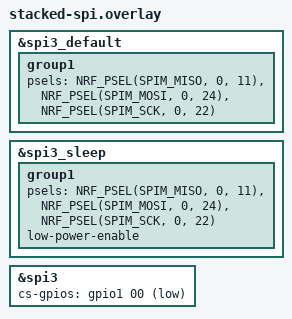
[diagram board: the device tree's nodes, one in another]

// Disable i2c

/* &i2c0_default {
    group1 {
        psels = <NRF_PSEL(TWIM_SDA, 1, 13)>, <NRF_PSEL(TWIM_SCL, 1, 15)>;
    };
};

&i2c0_sleep {
    group1 {
        psels = <NRF_PSEL(TWIM_SDA, 1, 13)>, <NRF_PSEL(TWIM_SCL, 1, 15)>;
    };
}; */

/delete-node/ &imu;
/delete-node/ &mag;




&spi3_default {
    group1 {
        psels = <NRF_PSEL(SPIM_MISO, 0, 11)>, // (SDO) SD0 On module
                <NRF_PSEL(SPIM_MOSI, 0, 24)>, // (SDI) SDA On module
                <NRF_PSEL(SPIM_SCK, 0, 22)>;  // SCL On module (Same as i2c clock)
    };
};

&spi3_sleep {
    group1 {
        psels = <NRF_PSEL(SPIM_MISO, 0, 11)>,
                <NRF_PSEL(SPIM_MOSI, 0, 24)>,
                <NRF_PSEL(SPIM_SCK, 0, 22)>;
        low-power-enable;
    };
};

&spi3 {
	cs-gpios = <&gpio1 00 GPIO_ACTIVE_LOW>;
};
